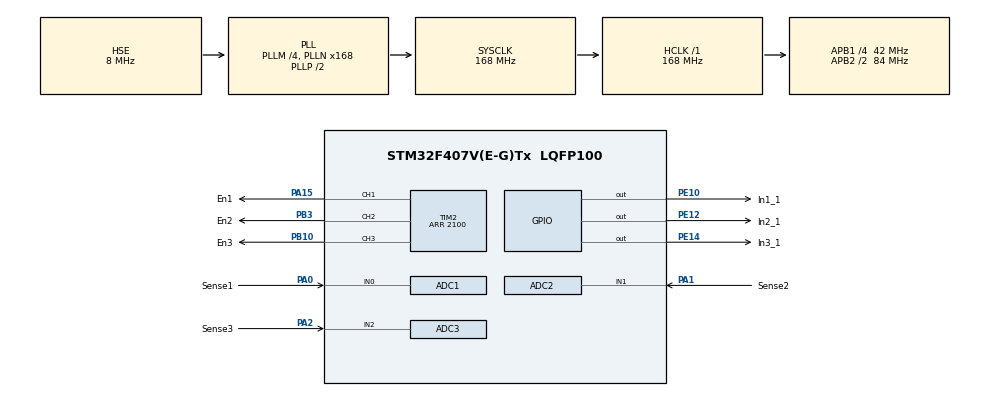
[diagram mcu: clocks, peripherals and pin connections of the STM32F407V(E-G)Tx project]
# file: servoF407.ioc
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ADC1.Channel-0\#ChannelRegularConversion=ADC_CHANNEL_0
ADC1.ContinuousConvMode=DISABLE
ADC1.ExternalTrigConv=ADC_EXTERNALTRIGCONV_T2_TRGO
ADC1.NbrOfConversionFlag=1
ADC1.Rank-0\#ChannelRegularConversion=1
ADC1.SamplingTime-0\#ChannelRegularConversion=ADC_SAMPLETIME_15CYCLES
ADC1.ScanConvMode=DISABLE
ADC1.master=1
ADC2.Channel-1\#ChannelRegularConversion=ADC_CHANNEL_1
ADC2.ContinuousConvMode=DISABLE
ADC2.ExternalTrigConv=ADC_EXTERNALTRIGCONV_T2_TRGO
ADC2.NbrOfConversionFlag=1
ADC2.Rank-1\#ChannelRegularConversion=1
ADC2.SamplingTime-1\#ChannelRegularConversion=ADC_SAMPLETIME_15CYCLES
ADC2.ScanConvMode=DISABLE
ADC3.Channel-0\#ChannelRegularConversion=ADC_CHANNEL_2
ADC3.ContinuousConvMode=DISABLE
ADC3.ExternalTrigConv=ADC_EXTERNALTRIGCONV_T2_TRGO
ADC3.NbrOfConversionFlag=1
ADC3.Rank-0\#ChannelRegularConversion=1
ADC3.SamplingTime-0\#ChannelRegularConversion=ADC_SAMPLETIME_15CYCLES
ADC3.ScanConvMode=DISABLE
Mcu.Family=STM32F4
Mcu.Name=STM32F407V(E-G)Tx
Mcu.Package=LQFP100
NVIC.ADC_IRQn=true\:0\:0\:false\:false\:true\:true\:true\:true
NVIC.PriorityGroup=NVIC_PRIORITYGROUP_4
PA0-WKUP.GPIO_Label=Sense1
PA0-WKUP.Signal=ADCx_IN0
PA1.GPIO_Label=Sense2
PA1.Signal=ADCx_IN1
PA15.GPIO_Label=En1
PA15.GPIO_Speed=GPIO_SPEED_FREQ_VERY_HIGH
PA15.Signal=S_TIM2_CH1_ETR
PA2.GPIO_Label=Sense3
PA2.Signal=ADCx_IN2
PB10.GPIO_Label=En3
PB10.GPIO_Speed=GPIO_SPEED_FREQ_VERY_HIGH
PB10.Signal=S_TIM2_CH3
PB3.GPIO_Label=En2
PB3.GPIO_Speed=GPIO_SPEED_FREQ_VERY_HIGH
PB3.Signal=S_TIM2_CH2
PE10.GPIO_Label=In1_1 
PE10.GPIO_Speed=GPIO_SPEED_FREQ_HIGH
PE10.Signal=GPIO_Output
PE12.GPIO_Label=In2_1 
PE12.GPIO_Speed=GPIO_SPEED_FREQ_HIGH
PE12.Signal=GPIO_Output
PE14.GPIO_Label=In3_1 
PE14.GPIO_Speed=GPIO_SPEED_FREQ_HIGH
PE14.Signal=GPIO_Output
PH0-OSC_IN.Mode=HSE-External-Oscillator
PH0-OSC_IN.Signal=RCC_OSC_IN
PH1-OSC_OUT.Mode=HSE-External-Oscillator
PH1-OSC_OUT.Signal=RCC_OSC_OUT
ProjectManager.HeapSize=0x200
ProjectManager.StackSize=0x400
ProjectManager.TargetToolchain=STM32CubeIDE
RCC.48MHZClocksFreq_Value=84000000
RCC.AHBFreq_Value=168000000
RCC.APB1CLKDivider=RCC_HCLK_DIV4
RCC.APB1Freq_Value=42000000
RCC.APB1TimFreq_Value=84000000
RCC.APB2CLKDivider=RCC_HCLK_DIV2
RCC.APB2Freq_Value=84000000
RCC.APB2TimFreq_Value=168000000
RCC.CortexFreq_Value=168000000
RCC.HCLKFreq_Value=168000000
RCC.HSE_VALUE=8000000
RCC.HSI_VALUE=16000000
RCC.LSE_VALUE=32768
RCC.PLLM=4
RCC.PLLN=168
RCC.PLLSourceVirtual=RCC_PLLSOURCE_HSE
RCC.SYSCLKFreq_VALUE=168000000
RCC.SYSCLKSource=RCC_SYSCLKSOURCE_PLLCLK
RCC.VCOOutputFreq_Value=336000000
SH.ADCx_IN0.0=ADC1_IN0,IN0
SH.ADCx_IN1.0=ADC2_IN1,IN1
SH.ADCx_IN2.0=ADC3_IN2,IN2
SH.S_TIM2_CH1_ETR.0=TIM2_CH1,PWM Generation1 CH1
SH.S_TIM2_CH2.0=TIM2_CH2,PWM Generation2 CH2
SH.S_TIM2_CH3.0=TIM2_CH3,PWM Generation3 CH3
TIM2.AutoReloadPreload=TIM_AUTORELOAD_PRELOAD_ENABLE
TIM2.Channel-PWM\ Generation1\ CH1=TIM_CHANNEL_1
TIM2.Channel-PWM\ Generation2\ CH2=TIM_CHANNEL_2
TIM2.Channel-PWM\ Generation3\ CH3=TIM_CHANNEL_3
TIM2.CounterMode=TIM_COUNTERMODE_CENTERALIGNED1
TIM2.Period=2100
TIM2.TIM_MasterOutputTrigger=TIM_TRGO_UPDATE
TIM2.TIM_MasterSlaveMode=TIM_MASTERSLAVEMODE_DISABLE
VP_TIM2_VS_ClockSourceINT.Mode=Internal
board=custom

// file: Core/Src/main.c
/* USER CODE BEGIN Header */
/**
  ******************************************************************************
  * @file           : main.c
  * @brief          : Main program body
  ******************************************************************************
  * @attention
  *
  * Copyright (c) 2024 STMicroelectronics.
  * All rights reserved.
  *
  * This software is licensed under terms that can be found in the LICENSE file
  * in the root directory of this software component.
  * If no LICENSE file comes with this software, it is provided AS-IS.
  *
  ******************************************************************************
  */
/* USER CODE END Header */
#include "main.h"

ADC_HandleTypeDef hadc1;
ADC_HandleTypeDef hadc2;
ADC_HandleTypeDef hadc3;

TIM_HandleTypeDef htim2;

void SystemClock_Config(void);
static void MX_GPIO_Init(void);
static void MX_ADC1_Init(void);
static void MX_ADC2_Init(void);
static void MX_ADC3_Init(void);
static void MX_TIM2_Init(void);

/* USER CODE BEGIN 0 */
void ServoStart(void);
void ServoTimerHandler(void);
extern uint8_t volatile servo_timeout;
/* USER CODE END 0 */

int main(void)
{

  /* MCU Configuration--------------------------------------------------------*/

  /* Reset of all peripherals, Initializes the Flash interface and the Systick. */
  HAL_Init();

  /* Configure the system clock */
  SystemClock_Config();

  /* Initialize all configured peripherals */
  MX_GPIO_Init();
  MX_ADC1_Init();
  MX_ADC2_Init();
  MX_ADC3_Init();
  MX_TIM2_Init();
  /* USER CODE BEGIN 2 */
  __HAL_RCC_GPIOC_CLK_ENABLE();
  GPIO_InitTypeDef gpio = {.Pin = GPIO_PIN_1, .Mode = GPIO_MODE_OUTPUT_PP, .Pull = GPIO_NOPULL, .Speed = GPIO_SPEED_FREQ_HIGH, .Alternate = 0};
  HAL_GPIO_Init(GPIOC, &gpio);
  ServoStart();
  /* USER CODE END 2 */

  /* Infinite loop */
  /* USER CODE BEGIN WHILE */
  while (1)
  {
	  if (servo_timeout) {
		  servo_timeout = 0;
		  ServoTimerHandler();
	  }
    /* USER CODE END WHILE */

  }
}

void SystemClock_Config(void)
{
  RCC_OscInitTypeDef RCC_OscInitStruct = {0};
  RCC_ClkInitTypeDef RCC_ClkInitStruct = {0};

  /** Configure the main internal regulator output voltage
  */
  __HAL_RCC_PWR_CLK_ENABLE();
  __HAL_PWR_VOLTAGESCALING_CONFIG(PWR_REGULATOR_VOLTAGE_SCALE1);

  /** Initializes the RCC Oscillators according to the specified parameters
  * in the RCC_OscInitTypeDef structure.
  */
  RCC_OscInitStruct.OscillatorType = RCC_OSCILLATORTYPE_HSE;
  RCC_OscInitStruct.HSEState = RCC_HSE_ON;
  RCC_OscInitStruct.PLL.PLLState = RCC_PLL_ON;
  RCC_OscInitStruct.PLL.PLLSource = RCC_PLLSOURCE_HSE;
  RCC_OscInitStruct.PLL.PLLM = 4;
  RCC_OscInitStruct.PLL.PLLN = 168;
  RCC_OscInitStruct.PLL.PLLP = RCC_PLLP_DIV2;
  RCC_OscInitStruct.PLL.PLLQ = 4;
  if (HAL_RCC_OscConfig(&RCC_OscInitStruct) != HAL_OK)
  {
    Error_Handler();
  }

  /** Initializes the CPU, AHB and APB buses clocks
  */
  RCC_ClkInitStruct.ClockType = RCC_CLOCKTYPE_HCLK|RCC_CLOCKTYPE_SYSCLK
                              |RCC_CLOCKTYPE_PCLK1|RCC_CLOCKTYPE_PCLK2;
  RCC_ClkInitStruct.SYSCLKSource = RCC_SYSCLKSOURCE_PLLCLK;
  RCC_ClkInitStruct.AHBCLKDivider = RCC_SYSCLK_DIV1;
  RCC_ClkInitStruct.APB1CLKDivider = RCC_HCLK_DIV4;
  RCC_ClkInitStruct.APB2CLKDivider = RCC_HCLK_DIV2;

  if (HAL_RCC_ClockConfig(&RCC_ClkInitStruct, FLASH_LATENCY_5) != HAL_OK)
  {
    Error_Handler();
  }
}

static void MX_ADC1_Init(void)
{

  ADC_ChannelConfTypeDef sConfig = {0};

  /** Configure the global features of the ADC (Clock, Resolution, Data Alignment and number of conversion)
  */
  hadc1.Instance = ADC1;
  hadc1.Init.ClockPrescaler = ADC_CLOCK_SYNC_PCLK_DIV4;
  hadc1.Init.Resolution = ADC_RESOLUTION_12B;
  hadc1.Init.ScanConvMode = DISABLE;
  hadc1.Init.ContinuousConvMode = DISABLE;
  hadc1.Init.DiscontinuousConvMode = DISABLE;
  hadc1.Init.ExternalTrigConvEdge = ADC_EXTERNALTRIGCONVEDGE_RISING;
  hadc1.Init.ExternalTrigConv = ADC_EXTERNALTRIGCONV_T2_TRGO;
  hadc1.Init.DataAlign = ADC_DATAALIGN_RIGHT;
  hadc1.Init.NbrOfConversion = 1;
  hadc1.Init.DMAContinuousRequests = DISABLE;
  hadc1.Init.EOCSelection = ADC_EOC_SINGLE_CONV;
  if (HAL_ADC_Init(&hadc1) != HAL_OK)
  {
    Error_Handler();
  }

  /** Configure for the selected ADC regular channel its corresponding rank in the sequencer and its sample time.
  */
  sConfig.Channel = ADC_CHANNEL_0;
  sConfig.Rank = 1;
  sConfig.SamplingTime = ADC_SAMPLETIME_15CYCLES;
  if (HAL_ADC_ConfigChannel(&hadc1, &sConfig) != HAL_OK)
  {
    Error_Handler();
  }

}

static void MX_ADC2_Init(void)
{

  ADC_ChannelConfTypeDef sConfig = {0};

  /** Configure the global features of the ADC (Clock, Resolution, Data Alignment and number of conversion)
  */
  hadc2.Instance = ADC2;
  hadc2.Init.ClockPrescaler = ADC_CLOCK_SYNC_PCLK_DIV4;
  hadc2.Init.Resolution = ADC_RESOLUTION_12B;
  hadc2.Init.ScanConvMode = DISABLE;
  hadc2.Init.ContinuousConvMode = DISABLE;
  hadc2.Init.DiscontinuousConvMode = DISABLE;
  hadc2.Init.ExternalTrigConvEdge = ADC_EXTERNALTRIGCONVEDGE_RISING;
  hadc2.Init.ExternalTrigConv = ADC_EXTERNALTRIGCONV_T2_TRGO;
  hadc2.Init.DataAlign = ADC_DATAALIGN_RIGHT;
  hadc2.Init.NbrOfConversion = 1;
  hadc2.Init.DMAContinuousRequests = DISABLE;
  hadc2.Init.EOCSelection = ADC_EOC_SINGLE_CONV;
  if (HAL_ADC_Init(&hadc2) != HAL_OK)
  {
    Error_Handler();
  }

  /** Configure for the selected ADC regular channel its corresponding rank in the sequencer and its sample time.
  */
  sConfig.Channel = ADC_CHANNEL_1;
  sConfig.Rank = 1;
  sConfig.SamplingTime = ADC_SAMPLETIME_15CYCLES;
  if (HAL_ADC_ConfigChannel(&hadc2, &sConfig) != HAL_OK)
  {
    Error_Handler();
  }

}

static void MX_ADC3_Init(void)
{

  ADC_ChannelConfTypeDef sConfig = {0};

  /** Configure the global features of the ADC (Clock, Resolution, Data Alignment and number of conversion)
  */
  hadc3.Instance = ADC3;
  hadc3.Init.ClockPrescaler = ADC_CLOCK_SYNC_PCLK_DIV4;
  hadc3.Init.Resolution = ADC_RESOLUTION_12B;
  hadc3.Init.ScanConvMode = DISABLE;
  hadc3.Init.ContinuousConvMode = DISABLE;
  hadc3.Init.DiscontinuousConvMode = DISABLE;
  hadc3.Init.ExternalTrigConvEdge = ADC_EXTERNALTRIGCONVEDGE_RISING;
  hadc3.Init.ExternalTrigConv = ADC_EXTERNALTRIGCONV_T2_TRGO;
  hadc3.Init.DataAlign = ADC_DATAALIGN_RIGHT;
  hadc3.Init.NbrOfConversion = 1;
  hadc3.Init.DMAContinuousRequests = DISABLE;
  hadc3.Init.EOCSelection = ADC_EOC_SINGLE_CONV;
  if (HAL_ADC_Init(&hadc3) != HAL_OK)
  {
    Error_Handler();
  }

  /** Configure for the selected ADC regular channel its corresponding rank in the sequencer and its sample time.
  */
  sConfig.Channel = ADC_CHANNEL_2;
  sConfig.Rank = 1;
  sConfig.SamplingTime = ADC_SAMPLETIME_15CYCLES;
  if (HAL_ADC_ConfigChannel(&hadc3, &sConfig) != HAL_OK)
  {
    Error_Handler();
  }

}

static void MX_TIM2_Init(void)
{

  TIM_ClockConfigTypeDef sClockSourceConfig = {0};
  TIM_MasterConfigTypeDef sMasterConfig = {0};
  TIM_OC_InitTypeDef sConfigOC = {0};

  htim2.Instance = TIM2;
  htim2.Init.Prescaler = 0;
  htim2.Init.CounterMode = TIM_COUNTERMODE_CENTERALIGNED1;
  htim2.Init.Period = 2100;
  htim2.Init.ClockDivision = TIM_CLOCKDIVISION_DIV1;
  htim2.Init.AutoReloadPreload = TIM_AUTORELOAD_PRELOAD_ENABLE;
  if (HAL_TIM_Base_Init(&htim2) != HAL_OK)
  {
    Error_Handler();
  }
  sClockSourceConfig.ClockSource = TIM_CLOCKSOURCE_INTERNAL;
  if (HAL_TIM_ConfigClockSource(&htim2, &sClockSourceConfig) != HAL_OK)
  {
    Error_Handler();
  }
  if (HAL_TIM_PWM_Init(&htim2) != HAL_OK)
  {
    Error_Handler();
  }
  sMasterConfig.MasterOutputTrigger = TIM_TRGO_UPDATE;
  sMasterConfig.MasterSlaveMode = TIM_MASTERSLAVEMODE_DISABLE;
  if (HAL_TIMEx_MasterConfigSynchronization(&htim2, &sMasterConfig) != HAL_OK)
  {
    Error_Handler();
  }
  sConfigOC.OCMode = TIM_OCMODE_PWM1;
  sConfigOC.Pulse = 0;
  sConfigOC.OCPolarity = TIM_OCPOLARITY_HIGH;
  sConfigOC.OCFastMode = TIM_OCFAST_DISABLE;
  if (HAL_TIM_PWM_ConfigChannel(&htim2, &sConfigOC, TIM_CHANNEL_1) != HAL_OK)
  {
    Error_Handler();
  }
  if (HAL_TIM_PWM_ConfigChannel(&htim2, &sConfigOC, TIM_CHANNEL_2) != HAL_OK)
  {
    Error_Handler();
  }
  if (HAL_TIM_PWM_ConfigChannel(&htim2, &sConfigOC, TIM_CHANNEL_3) != HAL_OK)
  {
    Error_Handler();
  }
  HAL_TIM_MspPostInit(&htim2);

}

static void MX_GPIO_Init(void)
{
  GPIO_InitTypeDef GPIO_InitStruct = {0};

  /* GPIO Ports Clock Enable */
  __HAL_RCC_GPIOH_CLK_ENABLE();
  __HAL_RCC_GPIOA_CLK_ENABLE();
  __HAL_RCC_GPIOE_CLK_ENABLE();
  __HAL_RCC_GPIOB_CLK_ENABLE();

  /*Configure GPIO pin Output Level */
  HAL_GPIO_WritePin(GPIOE, In1_1_Pin|In2_1_Pin|In3_1_Pin, GPIO_PIN_RESET);

  /*Configure GPIO pins : In1_1_Pin In2_1_Pin In3_1_Pin */
  GPIO_InitStruct.Pin = In1_1_Pin|In2_1_Pin|In3_1_Pin;
  GPIO_InitStruct.Mode = GPIO_MODE_OUTPUT_PP;
  GPIO_InitStruct.Pull = GPIO_NOPULL;
  GPIO_InitStruct.Speed = GPIO_SPEED_FREQ_HIGH;
  HAL_GPIO_Init(GPIOE, &GPIO_InitStruct);

}

void Error_Handler(void)
{
  __disable_irq();
  while (1)
  {
  }
}
